# MIMXRT685S_cm33 register map
Vendor: nxp.com; File version: 1.0
CPU: CM33 r2p0, little endian, MPU, FPU, VTOR, 3 interrupt priority bits
Registers are 32-bit, read-write, reset 0x0 unless marked. A register's access mark holds for its fields unless they carry their own. Offsets are from the block's base; [hi:lo] are bit positions; lines under a group give offsets from that group; {n}, {i} and the like mark numbered series; 'fields as' and 'values as' point back to an identical list.

## SCB — System Control Block
Base 0xE000ED00
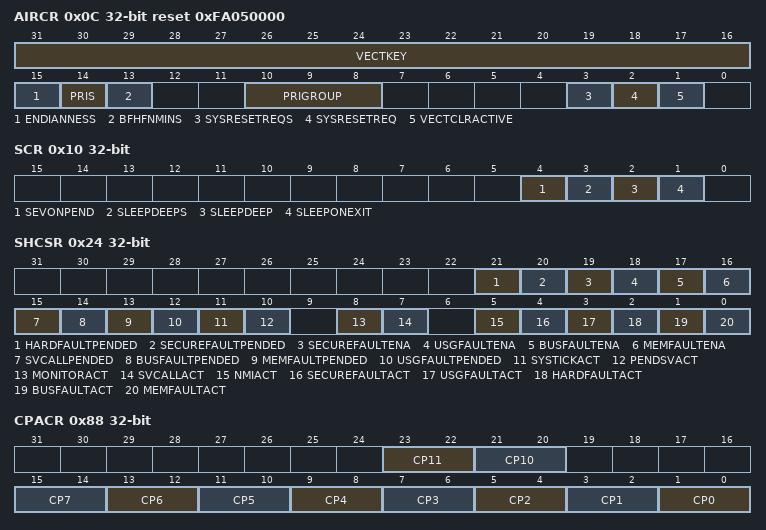
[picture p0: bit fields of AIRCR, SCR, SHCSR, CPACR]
0x0C AIRCR reset 0xFA050000 — Application Interrupt and Reset Control Register
  [31:16] VECTKEY ro — Register key: Reads as 0xFA05. On writes, write 0x5FA to VECTKEY, otherwise the write is ignored. This Field is not banked between Security states.
  [15] ENDIANNESS ro — Data endianness bit. This bit is not banked between Security states.
    0=LITTLE_ENDIAN; 1=BIG_ENDIAN
  [14] PRIS — Prioritize Secure exceptions. The value of this bit defines whether Secure exception priority boosting is enabled. This bit is not banked between Security states. RW from Secure state and RAZ/WI from Non-secure state.
    0=SAME_PRIORITY (Priority ranges of Secure and Non-secure exceptions are identical); 1=SECURE_PRIORITIZED (Non-secure exceptions are de-prioritized)
  [13] BFHFNMINS — BusFault, HardFault, and NMI Non-secure enable. The value of this bit defines whether BusFault and NMI exceptions are Non-secure, and whether exceptions target the Non-secure HardFault exception. This bit is not banked between Security states. RW from Secure-state and RO from Non-secure state.
    0=SECURE (BusFault, HardFault, and NMI are Secure.); 1=NON_SECURE (BusFault and NMI are Non-secure and exceptions can target Non-secure HardFault.)
  [10:8] PRIGROUP — Interrupt priority grouping field. This field determines the split of group priority from subpriority. This bit is banked between Security states
  [3] SYSRESETREQS — System reset request, Secure state only. The value of this bit defines whether the SYSRESETREQ bit is functional for Non-secure use. This bit is not banked between Security states. RW from Secure State and RAZ/WI from Non-secure state.
    0=SECURE_AND_NON_SECURE (SYSRESETREQ functionality is available to both Security states.); 1=SECURE_ONLY (SYSRESETREQ functionality is only available to Secure state.)
  [2] SYSRESETREQ — System reset request. This bit allows software or a debugger to request a system reset. This bit is not banked between Security states. RW if SYSRESETREQS is 0. When SYSRESETREQS is set to 1, from Non-secure state this bit acts as RAZ/WI.
    0=NO_REQUEST (Do not request a system reset.); 1=REQUEST_RESET (Request a system reset.)
  [1] VECTCLRACTIVE wo — Reserved for Debug use. This bit reads as 0. When writing to the register you must write 0 to this bit, otherwise behavior is UNPREDICTABLE. This bit is not banked between Security states.
0x10 SCR — The SCR controls features of entry to and exit from low-power state.
  [4] SEVONPEND — Send Event on Pending bit. When an event or interrupt enters pending state, the event signal wakes up the processor from WFE. If the processor is not waiting for an event, the event is registered and affects the next WFE. The processor also wakes up on execution of an SEV instruction or an external event. This bit is banked between Security states.
    0=EXCLUDE_DISABLED_INTERRUPTS (Only enabled interrupts or events can wakeup the processor, disabled interrupts are excluded.); 1=INCLUDE_DISABLED_INTERRUPTS (Enabled events and all interrupts, including disabled interrupts, can wakeup the processor)
  [3] SLEEPDEEPS — Controls whether the SLEEPDEEP bit is only accessible from the Secure state. This bit in only accessible from the Secure state, and behaves as RAZ/WI when accessed from the Nonsecure state. This bit is not banked between Security states.
    0=SECURE_AND_NON_SECURE (The SLEEPDEEP bit is accessible from both Security states.); 1=SECURE_ONLY (The SLEEPDEEP bit behaves as RAZ/WI when accessed from the Non-secure state.)
  [2] SLEEPDEEP — Controls whether the processor uses sleep or deep sleep as its low-power mode. This bit is not banked between Security states.
    0=SLEEP; 1=DEEP_SLEEP
  [1] SLEEPONEXIT — Indicates sleep-on-exit when returning from Handler mode to Thread mode. Setting this bit to 1 enables an interrupt driven application to avoid returning to an empty main application. This bit is banked between Security states.
    0=NOT_SLEEP (Do not sleep when returning to Thread mode.); 1=SLEEP (Enter sleep, or deep sleep, on return from an ISR)
0x24 SHCSR — System Handler Control and State Register
  [21] HARDFAULTPENDED — HardFault exception pended state
    0=DISABLED (HardFault exception modification is disabled.); 1=ENABLED (HardFault exception modification is enabled.)
  [20] SECUREFAULTPENDED — SecureFault exception pended state bit.
    0=DISABLED (SecureFault exception modification is disabled.); 1=ENABLED (SecureFault exception modification is enabled.)
  [19] SECUREFAULTENA — SecureFault exception enable.
    0=DISABLED (SecureFault exception is disabled.); 1=ENABLED (SecureFault exception is enabled.)
  [18] USGFAULTENA — UsageFault enable.
    0=DISABLED (UsageFault is disabled.); 1=ENABLED (UsageFault is enabled.)
  [17] BUSFAULTENA — BusFault enable.
    0=DISABLED (BusFault is disabled.); 1=ENABLED (BusFault is enabled.)
  [16] MEMFAULTENA — MemManage enable.
    0=DISABLED (MemManage exception is disabled.); 1=ENABLED (MemManage exception is enabled.)
  [15] SVCALLPENDED — SVCall pending.
    0=NOT_PENDING (SVCall exception is not pending.); 1=PENDING (SVCall exception is pending.)
  [14] BUSFAULTPENDED — BusFault exception pending.
    0=NOT_PENDING (BusFault exception is pending.); 1=PENDING (BusFault exception is not pending.)
  [13] MEMFAULTPENDED — MemManage exception pending.
    0=NOT_PENDING (MemManage exception is not pending.); 1=PENDING (MemManage exception is pending.)
  [12] USGFAULTPENDED — UsageFault exception pending.
    0=NOT_PENDING (UsageFault exception is not pending.); 1=PENDING (UsageFault exception is pending.)
  [11] SYSTICKACT — SysTick exception active.
    0=NOT_ACTIVE (SysTick exception is not active.); 1=ACTIVE (SysTick exception is active.)
  [10] PENDSVACT — PendSV exception active.
    0=NOT_ACTIVE (PendSV exception is not active.); 1=ACTIVE (PendSV exception is active.)
  [8] MONITORACT — Debug monitor active.
    0=NOT_ACTIVE (Debug monitor exception is not active.); 1=ACTIVE (Debug monitor exception is active.)
  [7] SVCALLACT — SVCall active.
    0=NOT_ACTIVE (SVCall exception is not active.); 1=ACTIVE (SVCall exception is active.)
  [5] NMIACT — NMI exception active.
    0=NOT_ACTIVE (NMI exception is not active.); 1=ACTIVE (NMI exception is active.)
  [4] SECUREFAULTACT — SecureFault exception active
    0=NOT_ACTIVE (SecureFault exception is not active.); 1=ACTIVE (SecureFault exception is active.)
  [3] USGFAULTACT — UsageFault exception active.
    0=NOT_ACTIVE (UsageFault exception is not active.); 1=ACTIVE (UsageFault exception is active.)
  [2] HARDFAULTACT — HardFault exception active.
    0=NOT_ACTIVE (HardFault exception is not active.); 1=ACTIVE (HardFault exception is active.)
  [1] BUSFAULTACT — BusFault exception active.
    0=NOT_ACTIVE (BusFault exception is not active.); 1=ACTIVE (BusFault exception is active.)
  [0] MEMFAULTACT — MemManage exception active.
    0=NOT_ACTIVE (MemManage exception is not active.); 1=ACTIVE (MemManage exception is active.)
0x88 CPACR reset not defined — Coprocessor Access Control Register
  [23:22] CP11 — CP11 Privilege.
    0=ACCESS_DENIED (Access Denied. All accesses to the Floating-point Extension result in NOCP UsageFault.); 1=PRIVILEGED_ONLY (Privileged access only. Unprivileged access to the Floatingpoint Extension result in NOCP UsageFault.); 3=FULL_ACCESS (Full access. Full access rights to the Floatingpoint Extension.)
  [21:20] CP10 — CP10 Privilege.
    values as CP11
  [2n+1:2n] CP{n} (n=0..7) — CP{n} Privilege.
    0=ACCESS_DENIED (Access Denied. Any attempted accesses to this coprocessor generates a NOCP UsageFault.); 1=PRIVILEGED_ONLY (Privileged access only. An unprivileged access generates a NOCP UsageFault.); 3=FULL_ACCESS (Full access. Full access rights for this coprocessor.)
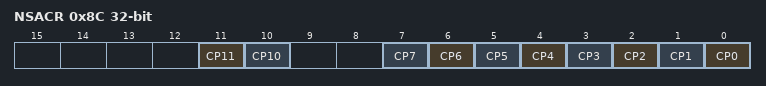
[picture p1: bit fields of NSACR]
0x8C NSACR reset not defined — Non-secure Access Control Register
  [11] CP11 — CP11 access.
  [10] CP10 — CP10 access.
    0=NOT_PERMITTED (Non-secure accesses to the Floating-point Extension generate a NOCP UsageFault.); 1=PERMITTED (Non-secure access to the Floatingpoint Extension permitted.)
  [n] CP{n} (n=0..7) — CP{n} access.
    0=NOT_PERMITTED (Non-secure accesses to this coprocessor generate a NOCP UsageFault.); 1=PERMITTED (Non-secure access to this coprocessor permitted.)
